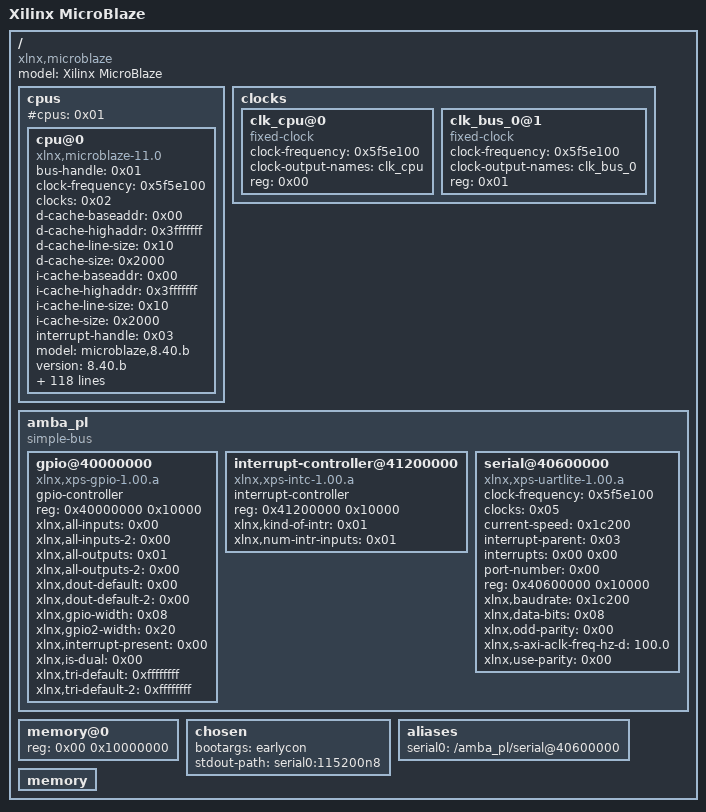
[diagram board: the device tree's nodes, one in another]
/dts-v1/;

/ {
	#address-cells = <0x01>;
	#size-cells = <0x01>;
	compatible = "xlnx,microblaze";
	model = "Xilinx MicroBlaze";

	cpus {
		#address-cells = <0x01>;
		#cpus = <0x01>;
		#size-cells = <0x00>;

		cpu@0 {
			bus-handle = <0x01>;
			clock-frequency = <0x5f5e100>;
			clocks = <0x02>;
			compatible = "xlnx,microblaze-11.0";
			d-cache-baseaddr = <0x00>;
			d-cache-highaddr = <0x3fffffff>;
			d-cache-line-size = <0x10>;
			d-cache-size = <0x2000>;
			device_type = "cpu";
			i-cache-baseaddr = <0x00>;
			i-cache-highaddr = <0x3fffffff>;
			i-cache-line-size = <0x10>;
			i-cache-size = <0x2000>;
			interrupt-handle = <0x03>;
			model = "microblaze,8.40.b";
			version = "8.40.b";
			memory = <0x04>;
			timebase-frequency = <0x5f5e100>;
			xlnx,addr-size = <0x20>;
			xlnx,addr-tag-bits = <0x11>;
			xlnx,allow-dcache-wr = <0x01>;
			xlnx,allow-icache-wr = <0x01>;
			xlnx,area-optimized = <0x00>;
			xlnx,async-interrupt = <0x01>;
			xlnx,async-wakeup = <0x03>;
			xlnx,avoid-primitives = <0x00>;
			xlnx,base-vectors = <0x00>;
			xlnx,branch-target-cache-size = <0x00>;
			xlnx,cache-byte-size = <0x2000>;
			xlnx,d-axi = <0x01>;
			xlnx,d-lmb = <0x01>;
			xlnx,d-lmb-mon = <0x00>;
			xlnx,daddr-size = <0x20>;
			xlnx,data-size = <0x20>;
			xlnx,dc-axi-mon = <0x00>;
			xlnx,dcache-addr-tag = <0x11>;
			xlnx,dcache-always-used = <0x00>;
			xlnx,dcache-byte-size = <0x2000>;
			xlnx,dcache-data-width = <0x00>;
			xlnx,dcache-force-tag-lutram = <0x00>;
			xlnx,dcache-line-len = <0x04>;
			xlnx,dcache-use-writeback = <0x00>;
			xlnx,dcache-victims = <0x00>;
			xlnx,debug-counter-width = <0x20>;
			xlnx,debug-enabled = <0x00>;
			xlnx,debug-event-counters = <0x05>;
			xlnx,debug-external-trace = <0x00>;
			xlnx,debug-interface = <0x00>;
			xlnx,debug-latency-counters = <0x01>;
			xlnx,debug-profile-size = <0x00>;
			xlnx,debug-trace-async-reset = <0x00>;
			xlnx,debug-trace-size = <0x2000>;
			xlnx,div-zero-exception = <0x00>;
			xlnx,dp-axi-mon = <0x00>;
			xlnx,dynamic-bus-sizing = <0x00>;
			xlnx,ecc-use-ce-exception = <0x00>;
			xlnx,edge-is-positive = <0x01>;
			xlnx,enable-discrete-ports = <0x00>;
			xlnx,endianness = <0x01>;
			xlnx,fault-tolerant = <0x00>;
			xlnx,fpu-exception = <0x00>;
			xlnx,freq = <0x5f5e100>;
			xlnx,fsl-exception = <0x00>;
			xlnx,fsl-links = <0x00>;
			xlnx,i-axi = <0x00>;
			xlnx,i-lmb = <0x01>;
			xlnx,i-lmb-mon = <0x00>;
			xlnx,iaddr-size = <0x20>;
			xlnx,ic-axi-mon = <0x00>;
			xlnx,icache-always-used = <0x00>;
			xlnx,icache-data-width = <0x00>;
			xlnx,icache-force-tag-lutram = <0x00>;
			xlnx,icache-line-len = <0x04>;
			xlnx,icache-streams = <0x00>;
			xlnx,icache-victims = <0x00>;
			xlnx,ill-opcode-exception = <0x00>;
			xlnx,imprecise-exceptions = <0x00>;
			xlnx,instr-size = <0x20>;
			xlnx,interconnect = <0x02>;
			xlnx,interrupt-is-edge = <0x00>;
			xlnx,interrupt-mon = <0x00>;
			xlnx,ip-axi-mon = <0x00>;
			xlnx,lmb-data-size = <0x20>;
			xlnx,lockstep-master = <0x00>;
			xlnx,lockstep-select = <0x00>;
			xlnx,lockstep-slave = <0x00>;
			xlnx,mmu-dtlb-size = <0x04>;
			xlnx,mmu-itlb-size = <0x02>;
			xlnx,mmu-privileged-instr = <0x00>;
			xlnx,mmu-tlb-access = <0x03>;
			xlnx,mmu-zones = <0x10>;
			xlnx,num-sync-ff-clk = <0x02>;
			xlnx,num-sync-ff-clk-debug = <0x02>;
			xlnx,num-sync-ff-clk-irq = <0x01>;
			xlnx,num-sync-ff-dbg-clk = <0x01>;
			xlnx,num-sync-ff-dbg-trace-clk = <0x02>;
			xlnx,number-of-pc-brk = <0x01>;
			xlnx,number-of-rd-addr-brk = <0x00>;
			xlnx,number-of-wr-addr-brk = <0x00>;
			xlnx,opcode-0x0-illegal = <0x00>;
			xlnx,optimization = <0x00>;
			xlnx,pc-width = <0x20>;
			xlnx,piaddr-size = <0x20>;
			xlnx,pvr = <0x00>;
			xlnx,pvr-user1 = <0x00>;
			xlnx,pvr-user2 = <0x00>;
			xlnx,reset-msr = <0x00>;
			xlnx,reset-msr-bip = <0x00>;
			xlnx,reset-msr-dce = <0x00>;
			xlnx,reset-msr-ee = <0x00>;
			xlnx,reset-msr-eip = <0x00>;
			xlnx,reset-msr-ice = <0x00>;
			xlnx,reset-msr-ie = <0x00>;
			xlnx,sco = <0x00>;
			xlnx,trace = <0x00>;
			xlnx,unaligned-exceptions = <0x00>;
			xlnx,use-barrel = <0x01>;
			xlnx,use-branch-target-cache = <0x00>;
			xlnx,use-config-reset = <0x00>;
			xlnx,use-dcache = <0x00>;
			xlnx,use-div = <0x01>;
			xlnx,use-ext-brk = <0x00>;
			xlnx,use-ext-nm-brk = <0x00>;
			xlnx,use-extended-fsl-instr = <0x00>;
			xlnx,use-fpu = <0x02>;
			xlnx,use-hw-mul = <0x01>;
			xlnx,use-icache = <0x00>;
			xlnx,use-interrupt = <0x01>;
			xlnx,use-mmu = <0x00>;
			xlnx,use-msr-instr = <0x00>;
			xlnx,use-non-secure = <0x00>;
			xlnx,use-pcmp-instr = <0x01>;
			xlnx,use-reorder-instr = <0x00>;
			xlnx,use-stack-protection = <0x00>;
		};
	};

	clocks {
		#address-cells = <0x01>;
		#size-cells = <0x00>;

		clk_cpu@0 {
			#clock-cells = <0x00>;
			clock-frequency = <0x5f5e100>;
			clock-output-names = "clk_cpu";
			compatible = "fixed-clock";
			reg = <0x00>;
			linux,phandle = <0x02>;
			phandle = <0x02>;
		};

		clk_bus_0@1 {
			#clock-cells = <0x00>;
			clock-frequency = <0x5f5e100>;
			clock-output-names = "clk_bus_0";
			compatible = "fixed-clock";
			reg = <0x01>;
			linux,phandle = <0x05>;
			phandle = <0x05>;
		};
	};

	amba_pl {
		#address-cells = <0x01>;
		#size-cells = <0x01>;
		compatible = "simple-bus";
		ranges;
		linux,phandle = <0x01>;
		phandle = <0x01>;

		gpio@40000000 {
			#gpio-cells = <0x02>;
			compatible = "xlnx,xps-gpio-1.00.a";
			gpio-controller;
			reg = <0x40000000 0x10000>;
			xlnx,all-inputs = <0x00>;
			xlnx,all-inputs-2 = <0x00>;
			xlnx,all-outputs = <0x01>;
			xlnx,all-outputs-2 = <0x00>;
			xlnx,dout-default = <0x00>;
			xlnx,dout-default-2 = <0x00>;
			xlnx,gpio-width = <0x08>;
			xlnx,gpio2-width = <0x20>;
			xlnx,interrupt-present = <0x00>;
			xlnx,is-dual = <0x00>;
			xlnx,tri-default = <0xffffffff>;
			xlnx,tri-default-2 = <0xffffffff>;
		};

		interrupt-controller@41200000 {
			#interrupt-cells = <0x02>;
			compatible = "xlnx,xps-intc-1.00.a";
			interrupt-controller;
			reg = <0x41200000 0x10000>;
			xlnx,kind-of-intr = <0x01>;
			xlnx,num-intr-inputs = <0x01>;
			linux,phandle = <0x03>;
			phandle = <0x03>;
		};

		serial@40600000 {
			clock-frequency = <0x5f5e100>;
			clocks = <0x05>;
			compatible = "xlnx,xps-uartlite-1.00.a";
			current-speed = <0x1c200>;
			device_type = "serial";
			interrupt-parent = <0x03>;
			interrupts = <0x00 0x00>;
			port-number = <0x00>;
			reg = <0x40600000 0x10000>;
			xlnx,baudrate = <0x1c200>;
			xlnx,data-bits = <0x08>;
			xlnx,odd-parity = <0x00>;
			xlnx,s-axi-aclk-freq-hz-d = "100.0";
			xlnx,use-parity = <0x00>;
		};
	};

	memory@0 {
		device_type = "memory";
		reg = <0x00 0x10000000>;
		linux,phandle = <0x04>;
		phandle = <0x04>;
	};

	chosen {
		bootargs = "earlycon";
		stdout-path = "serial0:115200n8";
	};

	aliases {
		serial0 = "/amba_pl/serial@40600000";
	};

	memory {
	};
};
